# R7FA4E10D register map
Vendor: Renesas Electronics Corporation; Series: RA4E1; File version: 1.20.00
CPU: CM33 r0p4, little endian, MPU, FPU, VTOR, 4 interrupt priority bits, 96 interrupts
Registers are 8-bit, read-write, reset 0x0 unless marked. A register's access mark holds for its fields unless they carry their own. Offsets are from the block's base; [hi:lo] are bit positions; 'fields as' and 'values as' point back to an identical list.

## POEG — Port Output Enable Module for GPT
Base 0x4008A000
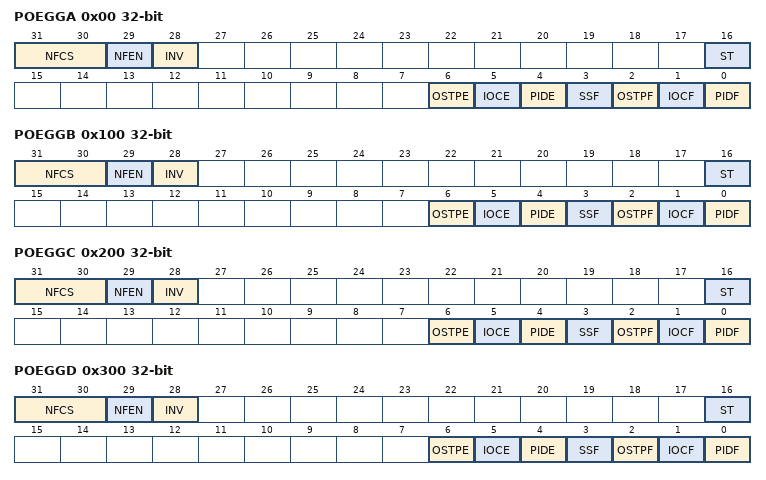
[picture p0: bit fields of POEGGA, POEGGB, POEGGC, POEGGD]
0x00 POEGGA 32-bit — POEG Group A Setting Register
  [31:30] NFCS — Noise Filter Clock Select
  [29] NFEN — Noise Filter Enable
  [28] INV — GTETRGn Input Reverse
  [16] ST ro — GTETRGn Input Status Flag
  [6] OSTPE — Oscillation Stop Detection Enable
  [5] IOCE — Enable for GPT Output,Disable Request
  [4] PIDE — Port Input Detection Enable
  [3] SSF — Software Stop Flag
  [2] OSTPF — Oscillation Stop Detection Flag
  [1] IOCF — Detection Flag for GPT Output,Disable Request
  [0] PIDF — Port Input Detection Flag
0x100 POEGGB 32-bit — POEG Group B Setting Register
  fields as POEGGA
0x200 POEGGC 32-bit — POEG Group C Setting Register
  fields as POEGGA
0x300 POEGGD 32-bit — POEG Group D Setting Register
  fields as POEGGA

## IIC0WU — Inter,Integrated Circuit 0 Wake,up Unit
Base 0x4009F014
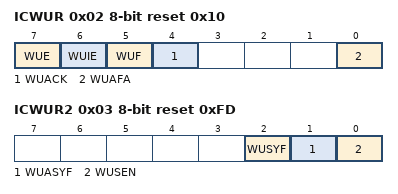
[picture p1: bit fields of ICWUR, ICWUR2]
0x02 ICWUR reset 0x10 — I2C Bus Wakeup Unit Register
  [7] WUE — Wakeup Function Enable
  [6] WUIE — Wakeup Interrupt Request Enable
  [5] WUF — Wakeup Event Occurrence Flag
  [4] WUACK — ACK Bit for Wakeup Mode
  [0] WUAFA — Wakeup Analog Filter Additional Selection
0x03 ICWUR2 reset 0xFD — I2C Bus Wakeup Unit Register 2
  [2] WUSYF ro — Wakeup Function Synchronous Operation Status Flag
  [1] WUASYF ro — Wakeup Function Asynchronous Operation Status Flag
  [0] WUSEN — Wakeup Function Synchronous Enable

## AGT0 — Low Power Asynchronous General Purpose Timer 0
Base 0x400E8000
Same registers: AGT1 0x400E8100, AGT2 0x400E8200, AGT3 0x400E8300, AGT5 0x400E8500
0x00 AGT 16-bit reset 0xFFFF — AGT Counter Register
0x02 AGTCMA 16-bit reset 0xFFFF — AGT Compare Match A Register
0x04 AGTCMB 16-bit reset 0xFFFF — AGT Compare Match B Register
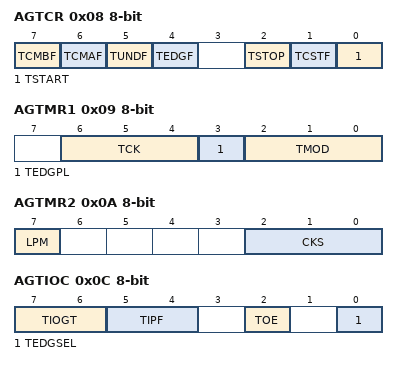
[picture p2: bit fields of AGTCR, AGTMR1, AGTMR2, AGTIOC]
0x08 AGTCR — AGT Control Register
  [7] TCMBF — Compare Match B Flag
  [6] TCMAF — Compare Match A Flag
  [5] TUNDF — Underflow Flag
  [4] TEDGF — Active Edge Judgment Flag
  [2] TSTOP wo — AGT Count Forced Stop
  [1] TCSTF ro — AGT Count Status Flag
  [0] TSTART — AGT Count Start
0x09 AGTMR1 — AGT Mode Register 1
  [6:4] TCK — Count Source
  [3] TEDGPL — Edge Polarity
  [2:0] TMOD — Operating Mode
0x0A AGTMR2 — AGT Mode Register 2
  [7] LPM — Low Power Mode
  [2:0] CKS — AGTLCLK or AGTSCLK Count Source Clock Frequency Division Ratio
0x0C AGTIOC — AGT I/O Control Register
  [7:6] TIOGT — Count Control
  [5:4] TIPF — Input Filter
  [2] TOE — AGTOn pin Output Enable
  [0] TEDGSEL — I/O Polarity Switch
0x0D AGTISR — AGT Event Pin Select Register
  [2] EEPS — AGTEEn Polarity Selection
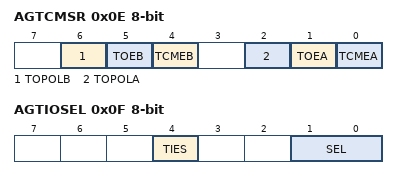
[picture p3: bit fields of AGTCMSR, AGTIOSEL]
0x0E AGTCMSR — AGT Compare Match Function Select Register
  [6] TOPOLB — AGTOBn Pin Polarity Select
  [5] TOEB — AGTOBn Pin Output Enable
  [4] TCMEB — AGT Compare Match B Register Enable
  [2] TOPOLA — AGTOAn Pin Polarity Select
  [1] TOEA — AGTOAn Pin Output Enable
  [0] TCMEA — AGT Compare Match A Register Enable
0x0F AGTIOSEL — AGT Pin Select Register
  [4] TIES — AGTIOn Pin Input Enable
  [1:0] SEL — AGTIOn Pin Select

## CRC — Cyclic Redundancy Check Calculator
Base 0x40108000
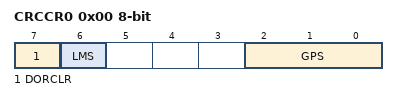
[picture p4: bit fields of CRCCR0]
0x00 CRCCR0 — CRC Control Register 0
  [7] DORCLR wo — CRCDOR/CRCDOR_HA/CRCDOR_BY Register Clear
  [6] LMS — CRC Calculation Switching
  [2:0] GPS — CRC Generating Polynomial Switching
0x04 CRCDIR 32-bit — CRC Data Input Register
0x04 CRCDIR_BY (alternate view of CRCDIR) — CRC Data Input Register
0x08 CRCDOR 32-bit — CRC Data Output Register
0x08 CRCDOR_HA 16-bit (alternate view of CRCDOR) — CRC Data Output Register
0x08 CRCDOR_BY (alternate view of CRCDOR) — CRC Data Output Register

## DOC — Data Operation Circuit
Base 0x40109000
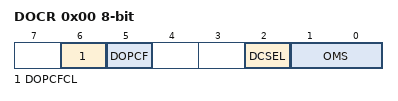
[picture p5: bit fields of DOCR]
0x00 DOCR — DOC Control Register
  [6] DOPCFCL — DOPCF Clear
  [5] DOPCF ro — DOC Flag
  [2] DCSEL — Detection Condition Select
  [1:0] OMS — Operating Mode Select
0x02 DODIR 16-bit — DOC Data Input Register
0x04 DODSR 16-bit — DOC Data Setting Register
